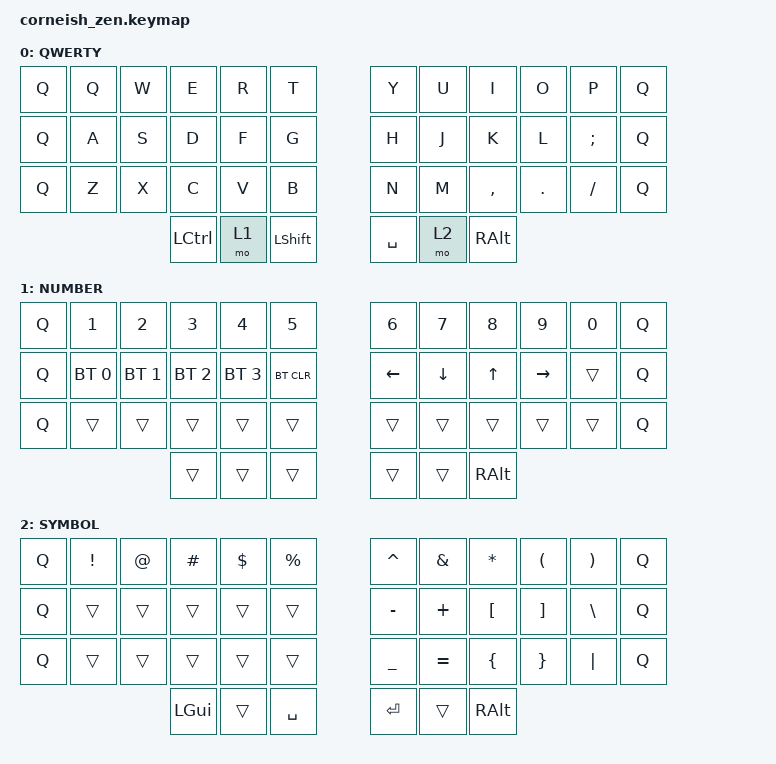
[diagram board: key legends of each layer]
#include <behaviors.dtsi>
#include <dt-bindings/zmk/keys.h>
#include <dt-bindings/zmk/bt.h>

/ {
  chosen {
    zmk,matrix_transform = &default_transform;
    //zmk,matrix_transform = &five_column_transform;
  };
};

/ {
        keymap {
                compatible = "zmk,keymap";

                default_layer {
                        label = "QWERTY";
// -----------------------------------------------------------------------------------------
// |  Q  |  W  |  E  |  R  |  T  |   |  Y  |  U   |  I  |  O  |  P  |
// |  A  |  S  |  D  |  F  |  G  |   |  H  |  J   |  K  |  L  |  ;  |
// |  Z  |  X  |  C  |  V  |  B  |   |  N  |  M   |  ,  |  .  |  /  |
//             | GUI | LWR | SHFT |   | SPC | RSE  | ALT |
                        bindings = <
   &kp Q   &kp Q &kp W &kp E &kp R &kp T   &kp Y &kp U  &kp I     &kp O   &kp P    &kp Q
   &kp Q   &kp A &kp S &kp D &kp F &kp G   &kp H &kp J  &kp K     &kp L   &kp SEMI &kp Q
   &kp Q   &kp Z &kp X &kp C &kp V &kp B   &kp N &kp M  &kp COMMA &kp DOT &kp FSLH &kp Q
                &kp LCTRL &mo 1 &kp LSHFT   &kp SPACE &mo 2 &kp RALT
                        >;
                };
                lower_layer {
                        label = "NUMBER";
// -----------------------------------------------------------------------------------------
// |  1  |  2  |  3  |  4  |  5  |   |  6  |  7  |  8  |  9  |  0  |
// | BT1 | BT2 | BT3 | BT4 | BT5 |   | LFT | DWN |  UP | RGT |     |      
// |     |     |     |     |     |   |     |     |     |     |     |      
//             | GUI |     | SPC |   | ENT |     | ALT |
                        bindings = <
   &kp Q   &kp N1       &kp N2       &kp N3       &kp N4       &kp N5         &kp N6   &kp N7   &kp N8 &kp N9    &kp N0&kp Q
  &kp Q    &bt BT_SEL 0 &bt BT_SEL 1 &bt BT_SEL 2 &bt BT_SEL 3 &bt BT_CLR   &kp LEFT &kp DOWN &kp UP &kp RIGHT &trans &kp Q
&kp Q      &trans       &trans       &trans       &trans       &trans         &trans   &trans   &trans &trans    &trans &kp Q
 	        &trans      &trans       &trans      &trans      &trans     &kp RALT
                        >;
                };

                raise_layer {
                        label = "SYMBOL";
// -----------------------------------------------------------------------------------------
// |  !  |  @  |  #  |  $  |  %  |   |  ^  |  &  |  *  |  (  |  )  |
// |     |     |     |     |     |   |  -  |  =  |  [  |  ]  |  \  |
// |     |     |     |     |     |   |  _  |  +  |  {  |  }  | "|" |
//                    | GUI |     | SPC |   | ENT |     | ALT |
                        bindings = <
  &kp Q    &kp EXCL &kp AT &kp HASH &kp DLLR &kp PRCNT   &kp CARET &kp AMPS  &kp STAR &kp LPAR &kp RPAR &kp Q
   &kp Q   &trans &trans &trans   &trans   &trans      &kp MINUS &kp PLUS  &kp LBKT &kp RBKT &kp BSLH &kp Q
&kp Q      &trans   &trans &trans   &trans   &trans      &kp UNDER &kp EQUAL &kp LBRC &kp RBRC &kp PIPE &kp Q
            &kp LGUI &trans   &kp SPACE   &kp RET   &trans    &kp RALT
            >;
                };
        };

combos {
    compatible = "zmk,combos";

        tst_combo {
        timeout-ms = <22>;
        key-positions = <4 5>; // they seem "right" - because we start with 0, not 1...
        bindings = <&kp RET>;
    };
        ctrl_backsp {
        timeout-ms = <22>;
        key-positions = <19 20>; // Update these numbers to the correct key positions
        bindings = <&kp LC(BSPC)>;
    };
        backsp {
        timeout-ms = <22>;
        key-positions = <20 21>; // Update these numbers to the correct key positions
        bindings = <&kp BSPC>;
    };
        return_key {
        timeout-ms = <22>;
        key-positions = <21 22>; // for next row, for some reason, add 12!
        bindings = <&kp RET>;
    };
        home_enter_up {
        timeout-ms = <22>;
        key-positions = <33 34>; // Update these numbers to the correct key positions
        bindings = <&kp HOME &kp RET &kp UP>;
    };

    // Add additional combos here with the same format
    // ...

        };
};
